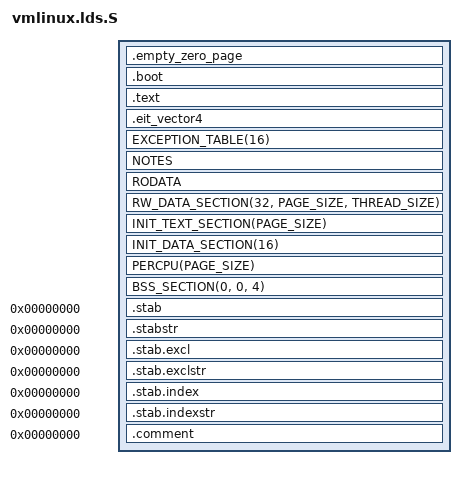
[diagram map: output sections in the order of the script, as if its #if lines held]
/* Copyright Statement:
 *
 * This software/firmware and related documentation ("MediaTek Software") are
 * protected under relevant copyright laws. The information contained herein
 * is confidential and proprietary to MediaTek Inc. and/or its licensors.
 * Without the prior written permission of MediaTek inc. and/or its licensors,
 * any reproduction, modification, use or disclosure of MediaTek Software,
 * and information contained herein, in whole or in part, shall be strictly prohibited.
 *
 * MediaTek Inc. (C) 2010. All rights reserved.
 *
 * BY OPENING THIS FILE, RECEIVER HEREBY UNEQUIVOCALLY ACKNOWLEDGES AND AGREES
 * THAT THE SOFTWARE/FIRMWARE AND ITS DOCUMENTATIONS ("MEDIATEK SOFTWARE")
 * RECEIVED FROM MEDIATEK AND/OR ITS REPRESENTATIVES ARE PROVIDED TO RECEIVER ON
 * AN "AS-IS" BASIS ONLY. MEDIATEK EXPRESSLY DISCLAIMS ANY AND ALL WARRANTIES,
 * EXPRESS OR IMPLIED, INCLUDING BUT NOT LIMITED TO THE IMPLIED WARRANTIES OF
 * MERCHANTABILITY, FITNESS FOR A PARTICULAR PURPOSE OR NONINFRINGEMENT.
 * NEITHER DOES MEDIATEK PROVIDE ANY WARRANTY WHATSOEVER WITH RESPECT TO THE
 * SOFTWARE OF ANY THIRD PARTY WHICH MAY BE USED BY, INCORPORATED IN, OR
 * SUPPLIED WITH THE MEDIATEK SOFTWARE, AND RECEIVER AGREES TO LOOK ONLY TO SUCH
 * THIRD PARTY FOR ANY WARRANTY CLAIM RELATING THERETO. RECEIVER EXPRESSLY ACKNOWLEDGES
 * THAT IT IS RECEIVER'S SOLE RESPONSIBILITY TO OBTAIN FROM ANY THIRD PARTY ALL PROPER LICENSES
 * CONTAINED IN MEDIATEK SOFTWARE. MEDIATEK SHALL ALSO NOT BE RESPONSIBLE FOR ANY MEDIATEK
 * SOFTWARE RELEASES MADE TO RECEIVER'S SPECIFICATION OR TO CONFORM TO A PARTICULAR
 * STANDARD OR OPEN FORUM. RECEIVER'S SOLE AND EXCLUSIVE REMEDY AND MEDIATEK'S ENTIRE AND
 * CUMULATIVE LIABILITY WITH RESPECT TO THE MEDIATEK SOFTWARE RELEASED HEREUNDER WILL BE,
 * AT MEDIATEK'S OPTION, TO REVISE OR REPLACE THE MEDIATEK SOFTWARE AT ISSUE,
 * OR REFUND ANY SOFTWARE LICENSE FEES OR SERVICE CHARGE PAID BY RECEIVER TO
 * MEDIATEK FOR SUCH MEDIATEK SOFTWARE AT ISSUE.
 */

/* ld script to make M32R Linux kernel
 */

#include <asm-generic/vmlinux.lds.h>
#include <asm/addrspace.h>
#include <asm/page.h>
#include <asm/thread_info.h>

OUTPUT_ARCH(m32r)
#if defined(__LITTLE_ENDIAN__)
       jiffies = jiffies_64;
#else
       jiffies = jiffies_64 + 4;
#endif

kernel_entry = boot - 0x80000000;
ENTRY(kernel_entry)

SECTIONS
{
  . = CONFIG_MEMORY_START + __PAGE_OFFSET;
  eit_vector = .;

  . = . + 0x1000;
  .empty_zero_page : { *(.empty_zero_page) } = 0

  /* read-only */
  _text = .;			/* Text and read-only data */
  .boot : { *(.boot) } = 0
  .text : {
	HEAD_TEXT
	TEXT_TEXT
	SCHED_TEXT
	LOCK_TEXT
	*(.fixup)
	*(.gnu.warning)
	} = 0x9090
#ifdef CONFIG_SMP
  . = ALIGN(65536);
  .eit_vector4 : { *(.eit_vector4) }
#endif
  _etext = .;			/* End of text section */

  EXCEPTION_TABLE(16)
  NOTES

  RODATA
  RW_DATA_SECTION(32, PAGE_SIZE, THREAD_SIZE)
  _edata = .;			/* End of data section */

  /* will be freed after init */
  . = ALIGN(PAGE_SIZE);		/* Init code and data */
  __init_begin = .;
  INIT_TEXT_SECTION(PAGE_SIZE)
  INIT_DATA_SECTION(16)
  PERCPU(PAGE_SIZE)
  . = ALIGN(PAGE_SIZE);
  __init_end = .;
  /* freed after init ends here */

  BSS_SECTION(0, 0, 4)

  _end = . ;

  /* Stabs debugging sections.  */
  .stab 0 : { *(.stab) }
  .stabstr 0 : { *(.stabstr) }
  .stab.excl 0 : { *(.stab.excl) }
  .stab.exclstr 0 : { *(.stab.exclstr) }
  .stab.index 0 : { *(.stab.index) }
  .stab.indexstr 0 : { *(.stab.indexstr) }
  .comment 0 : { *(.comment) }

  /* Sections to be discarded */
  DISCARDS
}
